AUTOSAR XML (schema 4-2-2)
package /ComponentTypes
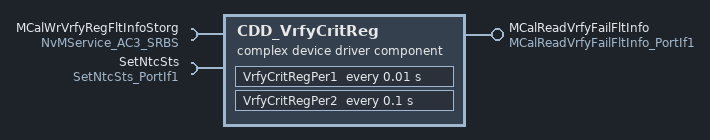
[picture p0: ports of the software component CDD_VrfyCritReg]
  complex device driver sw component type CDD_VrfyCritReg
    provide port MCalReadVrfyFailFltInfo: server-com-spec{operation=Oper, queue-length=1}, provided-interface=MCalReadVrfyFailFltInfo_PortIf1
    require port MCalWrVrfyRegFltInfoStorg: required-com-specs=[EraseBlock, GetErrorStatus, InvalidateNvBlock, ReadBlock, SetRamBlockStatus, WriteBlock], required-interface=NvMService_AC3_SRBS
    require port SetNtcSts: client-com-spec=Oper, required-interface=SetNtcSts_PortIf1
    behavior CDD_VrfyCritReg_InternalBehavior
      ar-typed-per-instance-memorys:
        8 x data, all with sw-calibration-access=READ-ONLY, type=uint32:
          dVrfyCritRegCritRegActVal
          dVrfyCritRegCritRegAdr
          dVrfyCritRegCritRegDesVal
          dVrfyCritRegSysCritRegActVal
          dVrfyCritRegSysCritRegAdr
          dVrfyCritRegSysCritRegDesVal
          MCalReadVrfyCritRegFltInfo
          MCalReadVrfyCritRegFltNvmInfo
      operation invoked event OIT_MCalReadVrfyFailFltInfo_Oper_MCalReadVrfyFailFltInfo_Oper: start-on-event=MCalReadVrfyFailFltInfo_Oper, operation=MCalReadVrfyFailFltInfo.Oper
      init event VrfyCritRegInit1_InitEvent: start-on-event=VrfyCritRegInit1
      timing event TMT_VrfyCritRegPer1: start-on-event=VrfyCritRegPer1, period=0.01
      timing event TMT_0_VrfyCritRegPer2: start-on-event=VrfyCritRegPer2, period=0.1
      4 x runnable:
        MCalReadVrfyFailFltInfo_Oper
        VrfyCritRegInit1
          sync call SC_MCalWrVrfyRegFltInfoStorg_GetErrorStatus: operation=MCalWrVrfyRegFltInfoStorg.GetErrorStatus, timeout=0
          sync call SC_MCalWrVrfyRegFltInfoStorg_SetRamBlockStatus: operation=MCalWrVrfyRegFltInfoStorg.SetRamBlockStatus, timeout=0
          sync call SC_SetNtcSts_Oper: operation=SetNtcSts.Oper, timeout=0
        VrfyCritRegPer1
          sync call SC_SetNtcSts_Oper: operation=SetNtcSts.Oper, timeout=0
        VrfyCritRegPer2
          sync call SC_MCalWrVrfyRegFltInfoStorg_SetRamBlockStatus: operation=MCalWrVrfyRegFltInfoStorg.SetRamBlockStatus, timeout=0
          sync call SC_SetNtcSts_Oper: operation=SetNtcSts.Oper, timeout=0
      swc service dependency MCalWrVrfyRegFltInfoStorg: assigned-datas=role-based-data-assignment={role=ramBlock, used-data-element=MCalReadVrfyCritRegFltNvmInfo}, assigned-ports=role-based-port-assignment={port-prototype=MCalWrVrfyRegFltInfoStorg, role=NvMService_AC3_SRBS}
        service-needs:
          nv block needs MCalWrVrfyRegFltInfoStorg: n-data-sets=0, ram-block-status-control=API, readonly=false, reliability=ERROR-DETECTION, resistant-to-changed-sw=true, restore-at-start=true, store-at-shutdown=true, write-only-once=false, writing-frequency=0, writing-priority=LOW
  swc implementation CDD_VrfyCritReg_Implementation: behavior=CDD_VrfyCritReg_InternalBehavior
    code-descriptors:
      code Default: artifact-descriptors=autosar-engineering-object={short-label=Default, category=SWSRC}
